# GD32E511_512 register map
File version: 1.0
CPU: CM33 r0p4, little endian, MPU, FPU, 4 interrupt priority bits
Registers are 32-bit, read-write, reset 0x0 unless marked. A register's access mark holds for its fields unless they carry their own. Offsets are from the block's base; [hi:lo] are bit positions; {n}, {i} and the like mark numbered series.

## SYSCFG_CMP — System configuration controller and Comparator
Base 0x40010000
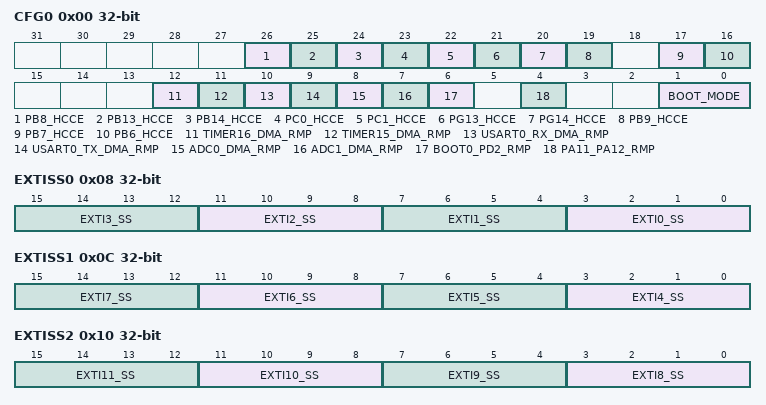
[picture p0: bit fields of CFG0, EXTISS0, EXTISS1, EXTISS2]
0x00 CFG0 access per field — System configuration register 0
  [26] PB8_HCCE rw — Fm+ mode on PB8 pin enable
  [25] PB13_HCCE rw — Fm+ mode on PB13 pin enable
  [24] PB14_HCCE rw — Fm+ mode on PB14 pin enable
  [23] PC0_HCCE rw — Fm+ mode on PC0 pin enable
  [22] PC1_HCCE rw — Fm+ mode on PC1 pin enable
  [21] PG13_HCCE rw — Fm+ mode on PG13 pin enable
  [20] PG14_HCCE rw — Fm+ mode on PG14 pin enable
  [19] PB9_HCCE rw — Fm+ mode on PB9 pin enable
  [17] PB7_HCCE rw — Fm+ mode on PB9 pin enable
  [16] PB6_HCCE rw — Fm+ mode on PB6 pin enable
  [12] TIMER16_DMA_RMP rw — Timer 16 DMA request remapping enable
  [11] TIMER15_DMA_RMP rw — Timer 15 DMA request remapping enable
  [10] USART0_RX_DMA_RMP rw — USART0_RX DMA request remapping enable
  [9] USART0_TX_DMA_RMP rw — USART0_TX DMA request remapping enable
  [8] ADC0_DMA_RMP rw — ADC0 DMA request remapping enable
  [7] ADC1_DMA_RMP rw — ADC1 DMA request remapping enable
  [6] BOOT0_PD2_RMP rw — BOOT0 and PD2 remapping bit.
  [4] PA11_PA12_RMP rw — PA11 and PA12 remapping bit for small packages (28 and 20 pins).
  [1:0] BOOT_MODE ro — Boot mode (Refer to Chapter Boot configuration for details)
0x08 EXTISS0 — EXTI sources selection register 0
  [4n+3:4n] EXTI{n}_SS (n=0..3) — EXTI {n} sources selection
0x0C EXTISS1 — EXTI sources selection register 1
  [4n-13:4n-16] EXTI{n}_SS (n=4..7) — EXTI {n} sources selection
0x10 EXTISS2 — EXTI sources selection register 2
  [4n-29:4n-32] EXTI{n}_SS (n=8..11) — EXTI {n} sources selection
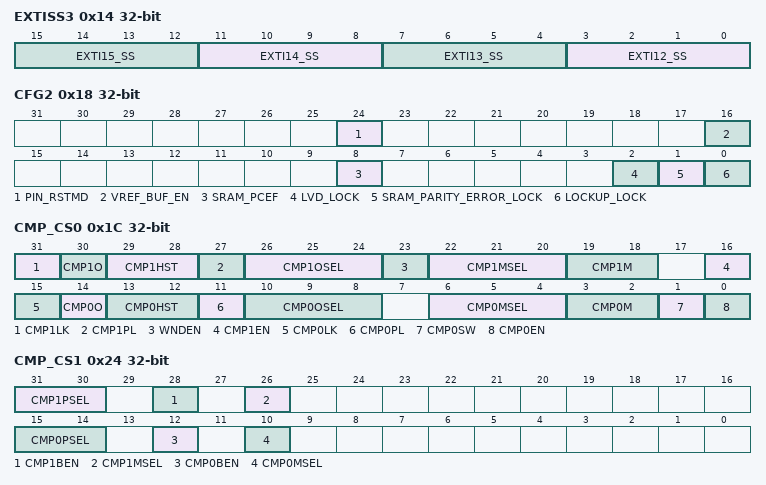
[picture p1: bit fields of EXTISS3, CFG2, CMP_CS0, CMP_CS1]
0x14 EXTISS3 — EXTI sources selection register 3
  [4n-45:4n-48] EXTI{n}_SS (n=12..15) — EXTI {n} sources selection
0x18 CFG2 — System configuration register 2
  [24] PIN_RSTMD — Pin reset mode
  [16] VREF_BUF_EN — VREF BUF enable
  [8] SRAM_PCEF — SRAM parity check error flag
  [2] LVD_LOCK
  [1] SRAM_PARITY_ERROR_LOCK — SRAM parity check error lock
  [0] LOCKUP_LOCK — Cortex-M33 LOCKUP output lock
0x1C CMP_CS0 access per field — CMP control/status register0
  [31] CMP1LK rw — CMP1 lock
  [30] CMP1O ro — CMP1 output state
  [29:28] CMP1HST rw — CMP1 hysteresis
  [27] CMP1PL rw — Polarity of CMP1 output
  [26:24] CMP1OSEL rw — CMP1 output selection
  [23] WNDEN rw — Window mode enable
  [22:20] CMP1MSEL rw — CMP1_IM input selection
  [19:18] CMP1M rw — CMP1 mode
  [16] CMP1EN rw — CMP1 enable.
  [15] CMP0LK rw — CMP0 lock
  [14] CMP0O ro — CMP0 output state
  [13:12] CMP0HST rw — CMP0 hysteresis
  [11] CMP0PL rw — Polarity of CMP0 output
  [10:8] CMP0OSEL rw — CMP0 output selection
  [6:4] CMP0MSEL rw — CMP0_IM input selection
  [3:2] CMP0M rw — CMP0 mode
  [1] CMP0SW rw — CMP0 switch
  [0] CMP0EN rw — CMP0 enable.
0x24 CMP_CS1 — CMP control/status register1
  [31:30] CMP1PSEL — CMP1_IP input selection
  [28] CMP1BEN — Scaler bridge enable bit
  [26] CMP1MSEL — CMP1_IM input selection
  [15:14] CMP0PSEL — CMP0_IP input selection
  [12] CMP0BEN — Scaler bridge enable bit
  [10] CMP0MSEL — CMP0_IM input selection
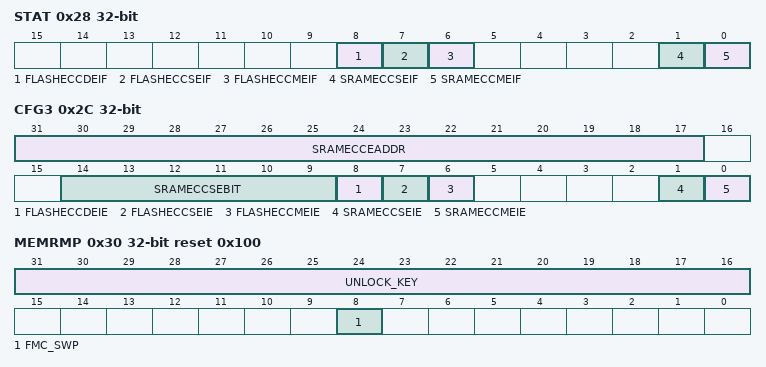
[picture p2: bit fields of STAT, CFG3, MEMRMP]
0x28 STAT — System status register
  [8] FLASHECCDEIF — Flash double bit non-correction error flag
  [7] FLASHECCSEIF — Flash single-bit correction error flag.
  [6] FLASHECCMEIF — Flash multi-bit non-correction error flag.
  [1] SRAMECCSEIF — SRAM single-bit correction error flag
  [0] SRAMECCMEIF — SRAM multi-bit non-correction error flag
0x2C CFG3 access per field — System configuration register 3
  [31:17] SRAMECCEADDR ro — Indicates the last ECC event on SRAMC occurred.
  [14:9] SRAMECCSEBIT ro — Indicates the error bit
  [8] FLASHECCDEIE rw — FLASH double bit non-correction interrupt enable
  [7] FLASHECCSEIE rw — FLASH single-bit correction interrupt enable
  [6] FLASHECCMEIE rw — FLASH multi-bit non-correction interrupt enable
  [1] SRAMECCSEIE rw — SRAM single-bit correction interrupt enable
  [0] SRAMECCMEIE rw — SRAM multi-bit non-correction interrupt enable
0x30 MEMRMP access per field reset 0x100 — Memory remap register
  [31:16] UNLOCK_KEY wo — Write 0xCDEF to this bit field to unlock flash bank mode, and write the FB_SWP bit is valid.
  [8] FMC_SWP rw — Flash Bank mode selection
